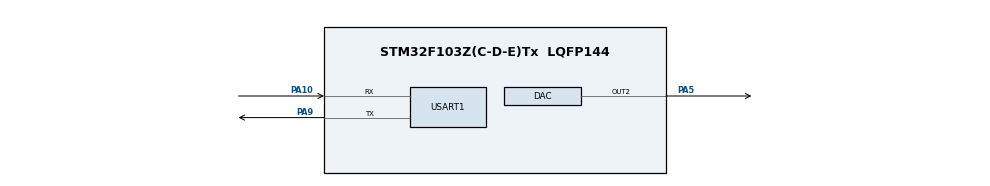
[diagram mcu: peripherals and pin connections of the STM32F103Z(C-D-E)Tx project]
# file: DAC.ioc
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DAC.DAC_Trigger2=DAC_TRIGGER_T2_TRGO
DAC.TriangleAmplitude2=DAC_TRIANGLEAMPLITUDE_4095
DAC.WaveGeneration2=TriangleWaveGeneration
Mcu.Family=STM32F1
Mcu.Name=STM32F103Z(C-D-E)Tx
Mcu.Package=LQFP144
NVIC.PriorityGroup=NVIC_PRIORITYGROUP_4
PA10.Mode=Asynchronous
PA10.Signal=USART1_RX
PA5.Signal=COMP_DAC2_group
PA9.Mode=Asynchronous
PA9.Signal=USART1_TX
ProjectManager.HeapSize=0x200
ProjectManager.StackSize=0x400
ProjectManager.TargetToolchain=MDK-ARM V5
RCC.APB1Freq_Value=8000000
RCC.APB2Freq_Value=8000000
SH.COMP_DAC2_group.0=DAC_OUT2,DAC_OUT2
TIM2.Period=0x0A
TIM2.Prescaler=0x02
TIM2.TIM_MasterOutputTrigger=TIM_TRGO_UPDATE
VP_SYS_VS_ND.Mode=No_Debug
VP_TIM2_VS_ClockSourceITR.Mode=TriggerSource_ITR1
board=DAC

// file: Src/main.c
/**
  ******************************************************************************
  * File Name          : main.c
  * Description        : Main program body
  ******************************************************************************
  *
  * COPYRIGHT(c) 2016 STMicroelectronics
  *
  * Redistribution and use in source and binary forms, with or without modification,
  * are permitted provided that the following conditions are met:
  *   1. Redistributions of source code must retain the above copyright notice,
  *      this list of conditions and the following disclaimer.
  *   2. Redistributions in binary form must reproduce the above copyright notice,
  *      this list of conditions and the following disclaimer in the documentation
  *      and/or other materials provided with the distribution.
  *   3. Neither the name of STMicroelectronics nor the names of its contributors
  *      may be used to endorse or promote products derived from this software
  *      without specific prior written permission.
  *
  * THIS SOFTWARE IS PROVIDED BY THE COPYRIGHT HOLDERS AND CONTRIBUTORS "AS IS"
  * AND ANY EXPRESS OR IMPLIED WARRANTIES, INCLUDING, BUT NOT LIMITED TO, THE
  * IMPLIED WARRANTIES OF MERCHANTABILITY AND FITNESS FOR A PARTICULAR PURPOSE ARE
  * DISCLAIMED. IN NO EVENT SHALL THE COPYRIGHT HOLDER OR CONTRIBUTORS BE LIABLE
  * FOR ANY DIRECT, INDIRECT, INCIDENTAL, SPECIAL, EXEMPLARY, OR CONSEQUENTIAL
  * DAMAGES (INCLUDING, BUT NOT LIMITED TO, PROCUREMENT OF SUBSTITUTE GOODS OR
  * SERVICES; LOSS OF USE, DATA, OR PROFITS; OR BUSINESS INTERRUPTION) HOWEVER
  * CAUSED AND ON ANY THEORY OF LIABILITY, WHETHER IN CONTRACT, STRICT LIABILITY,
  * OR TORT (INCLUDING NEGLIGENCE OR OTHERWISE) ARISING IN ANY WAY OUT OF THE USE
  * OF THIS SOFTWARE, EVEN IF ADVISED OF THE POSSIBILITY OF SUCH DAMAGE.
  *
  ******************************************************************************
  */
#include "main.h"
#include "stm32f1xx_hal.h"
#include "dac.h"
#include "tim.h"
#include "usart.h"
#include "gpio.h"

/* USER CODE BEGIN PV */
/* Private variables ---------------------------------------------------------*/

/* USER CODE END PV */

void SystemClock_Config(void);
void Error_Handler(void);

/* USER CODE BEGIN PFP */
/* Private function prototypes -----------------------------------------------*/

/* USER CODE END PFP */

int main(void)
{

  /* MCU Configuration----------------------------------------------------------*/

  /* Reset of all peripherals, Initializes the Flash interface and the Systick. */
  HAL_Init();

  /* Configure the system clock */
  SystemClock_Config();

  /* Initialize all configured peripherals */
  MX_GPIO_Init();
  MX_DAC_Init();
  MX_USART1_UART_Init();
  MX_TIM2_Init();

  /* USER CODE BEGIN 2 */
  printf("\r\nDAC EXAMPLE\r\n");
  /*##-1- Start the TIM Base generation in interrupt mode ####################*/
  HAL_TIM_Base_Start(&htim2);

  /*##-2- Enable DAC Channel2 ################################################*/
  HAL_DAC_Start(&hdac, DAC_CHANNEL_2);
  /* USER CODE END 2 */

  /* Infinite loop */
  while (1)
  {

  }

}

/** System Clock Configuration
*/
void SystemClock_Config(void)
{

  RCC_OscInitTypeDef RCC_OscInitStruct;
  RCC_ClkInitTypeDef RCC_ClkInitStruct;

    /**Initializes the CPU, AHB and APB busses clocks
    */
  RCC_OscInitStruct.OscillatorType = RCC_OSCILLATORTYPE_HSI;
  RCC_OscInitStruct.HSIState = RCC_HSI_ON;
  RCC_OscInitStruct.HSICalibrationValue = 16;
  RCC_OscInitStruct.PLL.PLLState = RCC_PLL_NONE;
  if (HAL_RCC_OscConfig(&RCC_OscInitStruct) != HAL_OK)
  {
    Error_Handler();
  }

    /**Initializes the CPU, AHB and APB busses clocks
    */
  RCC_ClkInitStruct.ClockType = RCC_CLOCKTYPE_HCLK|RCC_CLOCKTYPE_SYSCLK
                              |RCC_CLOCKTYPE_PCLK1|RCC_CLOCKTYPE_PCLK2;
  RCC_ClkInitStruct.SYSCLKSource = RCC_SYSCLKSOURCE_HSI;
  RCC_ClkInitStruct.AHBCLKDivider = RCC_SYSCLK_DIV1;
  RCC_ClkInitStruct.APB1CLKDivider = RCC_HCLK_DIV1;
  RCC_ClkInitStruct.APB2CLKDivider = RCC_HCLK_DIV1;

  if (HAL_RCC_ClockConfig(&RCC_ClkInitStruct, FLASH_LATENCY_0) != HAL_OK)
  {
    Error_Handler();
  }

    /**Configure the Systick interrupt time
    */
  HAL_SYSTICK_Config(HAL_RCC_GetHCLKFreq()/1000);

    /**Configure the Systick
    */
  HAL_SYSTICK_CLKSourceConfig(SYSTICK_CLKSOURCE_HCLK);

  /* SysTick_IRQn interrupt configuration */
  HAL_NVIC_SetPriority(SysTick_IRQn, 0, 0);
}

void Error_Handler(void)
{
  while(1)
  {
  }
}

/************************ (C) COPYRIGHT STMicroelectronics *****END OF FILE****/
